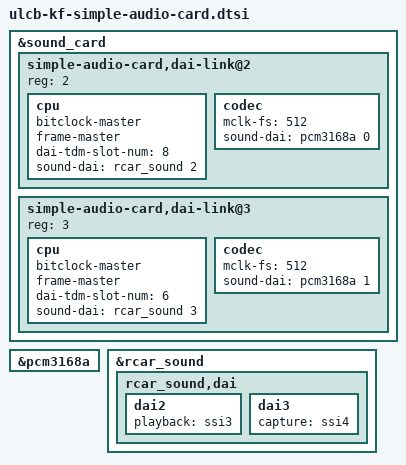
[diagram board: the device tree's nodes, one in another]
&sound_card {
	simple-audio-card,dai-link@2 {
		reg = <2>;
		cpu {
			bitclock-master;
			frame-master;
			dai-tdm-slot-num = <8>;
			sound-dai = <&rcar_sound 2>;
		};
		codec {
			mclk-fs = <512>;
			sound-dai = <&pcm3168a 0>;
		};
	};
	simple-audio-card,dai-link@3 {
		reg = <3>;
		cpu {
			bitclock-master;
			frame-master;
			dai-tdm-slot-num = <6>;
			sound-dai = <&rcar_sound 3>;
		};
		codec {
			mclk-fs = <512>;
			sound-dai = <&pcm3168a 1>;
		};
	};
};
&pcm3168a {
	#sound-dai-cells = <1>;
};
&rcar_sound {
	rcar_sound,dai {
		dai2 {
			playback = <&ssi3>;
		};
		dai3 {
			capture = <&ssi4>;
		};
	};
};
